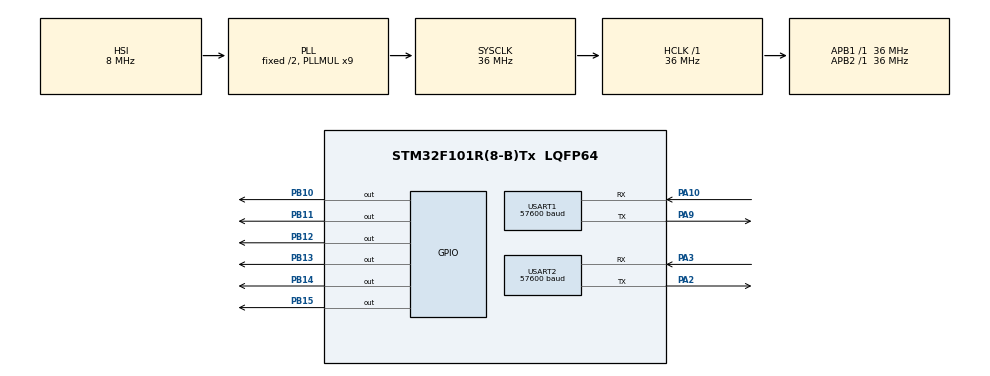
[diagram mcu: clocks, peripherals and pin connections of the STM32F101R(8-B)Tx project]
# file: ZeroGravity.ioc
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Mcu.Family=STM32F1
NVIC.DMA1_Channel6_IRQn=true\:0\:0\:false\:false\:true\:false\:true
PB10.PinState=GPIO_PIN_RESET
PD1-OSC_OUT.Mode=HSE-External-Oscillator
PA10.Mode=Asynchronous
USART1.BaudRate=57600
Dma.USART2_RX.0.Direction=DMA_PERIPH_TO_MEMORY
PD0-OSC_IN.Signal=RCC_OSC_IN
PB11.Signal=GPIO_Output
PB15.Signal=GPIO_Output
PB13.Signal=GPIO_Output
NVIC.USART2_IRQn=true\:0\:0\:true\:false\:true\:true\:true
USART2.BaudRate=57600
RCC.SYSCLKSource=RCC_SYSCLKSOURCE_PLLCLK
ProjectManager.StackSize=0x400
Dma.USART2_RX.0.Mode=DMA_CIRCULAR
PD1-OSC_OUT.Signal=RCC_OSC_OUT
PA13.Signal=SYS_JTMS-SWDIO
PA3.Mode=Asynchronous
PA9.Mode=Asynchronous
ProjectManager.TargetToolchain=STM32CubeIDE
Dma.USART2_RX.0.Priority=DMA_PRIORITY_LOW
Dma.USART2_RX.0.PeriphDataAlignment=DMA_PDATAALIGN_BYTE
RCC.HCLKFreq_Value=36000000
PA9.Signal=USART1_TX
RCC.AHBFreq_Value=36000000
PB10.Signal=GPIO_Output
PD0-OSC_IN.Mode=HSE-External-Oscillator
PB14.Signal=GPIO_Output
board=custom
RCC.PLLMUL=RCC_PLL_MUL9
RCC.APB2Freq_Value=36000000
Dma.USART2_RX.0.MemDataAlignment=DMA_MDATAALIGN_BYTE
PA14.Mode=Serial_Wire
Dma.USART2_RX.0.Instance=DMA1_Channel6
PA13.Mode=Serial_Wire
Mcu.Name=STM32F101R(8-B)Tx
Dma.USART2_RX.0.MemInc=DMA_MINC_ENABLE
PA2.Signal=USART2_TX
RCC.SYSCLKFreq_VALUE=36000000
Mcu.Package=LQFP64
Dma.USART2_RX.0.PeriphInc=DMA_PINC_DISABLE
USART2.VirtualMode=VM_ASYNC
USART1.VirtualMode=VM_ASYNC
PA10.Signal=USART1_RX
PA14.Signal=SYS_JTCK-SWCLK
ProjectManager.HeapSize=0x200
NVIC.PriorityGroup=NVIC_PRIORITYGROUP_4
RCC.APB1TimFreq_Value=36000000
PA2.Mode=Asynchronous
NVIC.USART1_IRQn=true\:0\:0\:false\:false\:true\:true\:true
Dma.Request0=USART2_RX
RCC.APB1Freq_Value=36000000
PB12.Signal=GPIO_Output
PA3.Signal=USART2_RX

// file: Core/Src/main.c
/* USER CODE BEGIN Header */
/**
  ******************************************************************************
  * @file           : main.c
  * @brief          : Main program body
  ******************************************************************************
  * @attention
  *
  * <h2><center>&copy; Copyright (c) 2021 STMicroelectronics.
  * All rights reserved.</center></h2>
  *
  * This software component is licensed by ST under BSD 3-Clause license,
  * the "License"; You may not use this file except in compliance with the
  * License. You may obtain a copy of the License at:
  *                        opensource.org/licenses/BSD-3-Clause
  *
  ******************************************************************************
  */
/* USER CODE END Header */
#include "main.h"
//#include "dma.h"
//#include "usart.h"
//#include "gpio.h"

/* USER CODE BEGIN Includes */
//#include "sh1106.h"
//#include "switch_control.h"
//#include "user_timer.h"
/* USER CODE END Includes */

void SystemClock_Config(void);

int main(void)
{

  /* MCU Configuration--------------------------------------------------------*/

  /* Reset of all peripherals, Initializes the Flash interface and the Systick. */
  HAL_Init();

  /* Configure the system clock */
  SystemClock_Config();

  /* Initialize all configured peripherals */
  MX_GPIO_Init();
  MX_DMA_Init();
  MX_USART2_UART_Init();
  MX_USART1_UART_Init();
  /* USER CODE BEGIN 2 */
//  sh1106_Init();
  Switch_Init();
  printf("ZeroGravity REV 0.1.1\r\n");
  /* USER CODE END 2 */

  /* Infinite loop */
  while (1)
  {

    /* USER CODE BEGIN 3 */
//	  sh1106_test();
	  Switch_Task();
	  Terminal_Task();
	  Bluetooth_Process();
  }
  /* USER CODE END 3 */
}

void SystemClock_Config(void)
{
  RCC_OscInitTypeDef RCC_OscInitStruct = {0};
  RCC_ClkInitTypeDef RCC_ClkInitStruct = {0};

  /** Initializes the RCC Oscillators according to the specified parameters
  * in the RCC_OscInitTypeDef structure.
  */
  RCC_OscInitStruct.OscillatorType = RCC_OSCILLATORTYPE_HSI;
  RCC_OscInitStruct.HSIState = RCC_HSI_ON;
  RCC_OscInitStruct.HSICalibrationValue = RCC_HSICALIBRATION_DEFAULT;
  RCC_OscInitStruct.PLL.PLLState = RCC_PLL_ON;
  RCC_OscInitStruct.PLL.PLLSource = RCC_PLLSOURCE_HSI_DIV2;
  RCC_OscInitStruct.PLL.PLLMUL = RCC_PLL_MUL9;
  if (HAL_RCC_OscConfig(&RCC_OscInitStruct) != HAL_OK)
  {
    Error_Handler();
  }
  /** Initializes the CPU, AHB and APB buses clocks
  */
  RCC_ClkInitStruct.ClockType = RCC_CLOCKTYPE_HCLK|RCC_CLOCKTYPE_SYSCLK
                              |RCC_CLOCKTYPE_PCLK1|RCC_CLOCKTYPE_PCLK2;
  RCC_ClkInitStruct.SYSCLKSource = RCC_SYSCLKSOURCE_PLLCLK;
  RCC_ClkInitStruct.AHBCLKDivider = RCC_SYSCLK_DIV1;
  RCC_ClkInitStruct.APB1CLKDivider = RCC_HCLK_DIV1;
  RCC_ClkInitStruct.APB2CLKDivider = RCC_HCLK_DIV1;

  if (HAL_RCC_ClockConfig(&RCC_ClkInitStruct, FLASH_LATENCY_1) != HAL_OK)
  {
    Error_Handler();
  }
}

void Error_Handler(void)
{
  __disable_irq();
  while (1)
  {
  }
}

/************************ (C) COPYRIGHT STMicroelectronics *****END OF FILE****/
